# STM8AL3146 register map
Vendor: STMicroelectronics; Series: STM8L/STM8AL, medium density; File version: 1.0
CPU: other r1p0, big endian, no MPU, no FPU, 4 interrupt priority bits
Registers are 8-bit, read-write, reset 0x0 unless marked. A register's access mark holds for its fields unless they carry their own. Offsets are from the block's base; [hi:lo] are bit positions; {n}, {i} and the like mark numbered series.

## SWIM
Base 0x00007F80
0x00 CSR — SWIM control status register

## TIM1
Base 0x000052B0
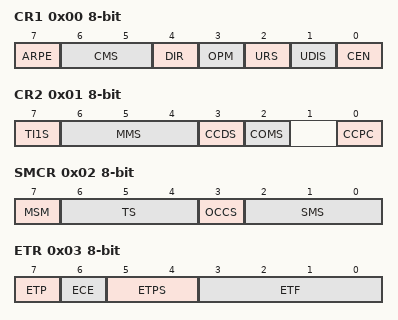
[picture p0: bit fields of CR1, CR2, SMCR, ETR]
0x00 CR1 — TIM1 control register 1
  [7] ARPE, [6:5] CMS, [4] DIR, [3] OPM, [2] URS, [1] UDIS, [0] CEN
0x01 CR2 — TIM1 control register 2
  [7] TI1S, [6:4] MMS, [3] CCDS, [2] COMS, [0] CCPC
0x02 SMCR — TIM1 Slave mode control register
  [7] MSM, [6:4] TS, [3] OCCS, [2:0] SMS
0x03 ETR — TIM1 external trigger register
  [7] ETP, [6] ECE, [5:4] ETPS, [3:0] ETF
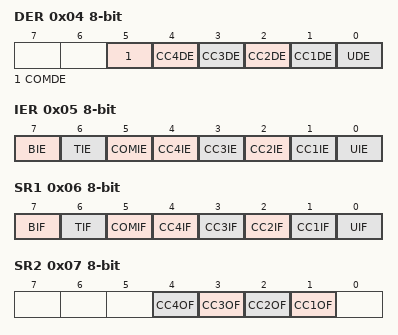
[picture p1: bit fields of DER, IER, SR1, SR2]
0x04 DER — TIM1 DMA1 request enable register
  [5] COMDE, [n] CC{n}DE (n=1..4), [0] UDE
0x05 IER — TIM1 Interrupt enable register
  [7] BIE, [6] TIE, [5] COMIE, [n] CC{n}IE (n=1..4), [0] UIE
0x06 SR1 — TIM1 status register 1
  [7] BIF, [6] TIF, [5] COMIF, [n] CC{n}IF (n=1..4), [0] UIF
0x07 SR2 — TIM1 status register 2
  [n] CC{n}OF (n=1..4)
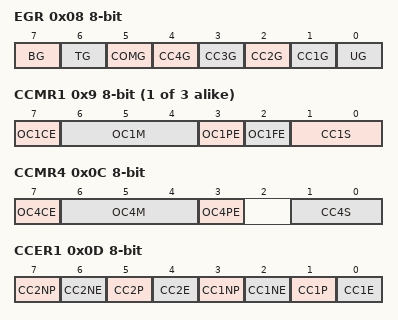
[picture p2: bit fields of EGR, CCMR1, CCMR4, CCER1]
0x08 EGR — TIM1 event generation register
  [7] BG, [6] TG, [5] COMG, [n] CC{n}G (n=1..4), [0] UG
{0x8+i} CCMR{i} (i=1..3) — TIM1 Capture/Compare mode register {i}
  [7] OC{i}CE, [6:4] OC{i}M, [3] OC{i}PE, [2] OC{i}FE, [1:0] CC{i}S
0x0C CCMR4 — TIM1 Capture/Compare mode register 4
  [7] OC4CE, [6:4] OC4M, [3] OC4PE, [1:0] CC4S
0x0D CCER1 — TIM1 Capture/Compare enable register 1
  [7] CC2NP, [6] CC2NE, [5] CC2P, [4] CC2E, [3] CC1NP, [2] CC1NE, [1] CC1P, [0] CC1E
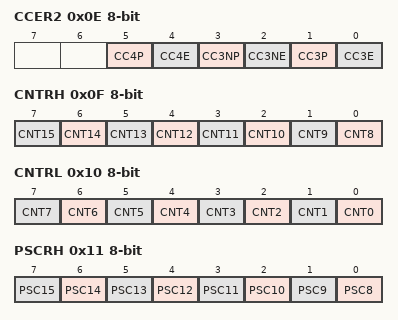
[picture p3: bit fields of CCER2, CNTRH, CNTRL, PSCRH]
0x0E CCER2 — TIM1 Capture/Compare enable register 2
  [5] CC4P, [4] CC4E, [3] CC3NP, [2] CC3NE, [1] CC3P, [0] CC3E
0x0F CNTRH — TIM1 counter high
  [n-8] CNT{n} (n=8..15)
0x10 CNTRL — TIM1 counter low
  [n] CNT{n} (n=0..7)
0x11 PSCRH — TIM1 prescaler register high
  [n-8] PSC{n} (n=8..15)
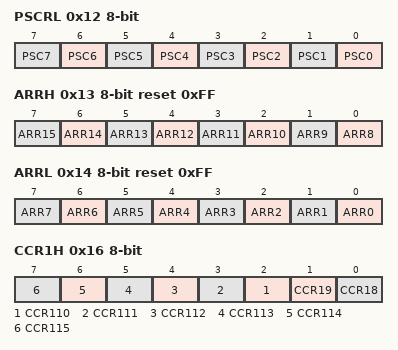
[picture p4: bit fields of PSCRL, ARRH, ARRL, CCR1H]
0x12 PSCRL — TIM1 prescaler register low
  [n] PSC{n} (n=0..7)
0x13 ARRH reset 0xFF — TIM1 Auto-reload register high
  [n-8] ARR{n} (n=8..15)
0x14 ARRL reset 0xFF — TIM1 Auto-reload register low
  [n] ARR{n} (n=0..7)
0x15 RCR — TIM1 Repetition counter register
  [7:0] REP
0x16 CCR1H — TIM1 Capture/Compare register 1 high
  [n-108] CCR{n} (n=110..115), [1] CCR19, [0] CCR18
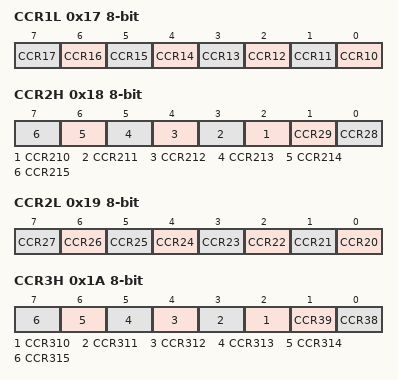
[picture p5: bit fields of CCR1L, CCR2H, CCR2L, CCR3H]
0x17 CCR1L — TIM1 Capture/Compare register 1 low
  [n-10] CCR{n} (n=10..17)
0x18 CCR2H — TIM1 Capture/Compare register 2 high
  [n-208] CCR{n} (n=210..215), [1] CCR29, [0] CCR28
0x19 CCR2L — TIM1 Capture/Compare register 2 low
  [n-20] CCR{n} (n=20..27)
0x1A CCR3H — TIM1 Capture/Compare register 3 high
  [n-308] CCR{n} (n=310..315), [1] CCR39, [0] CCR38
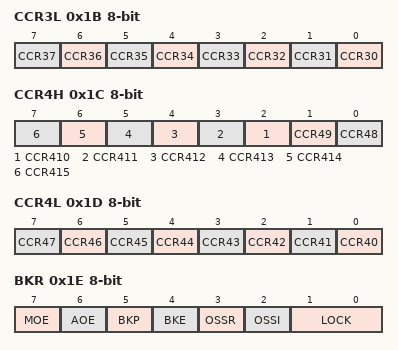
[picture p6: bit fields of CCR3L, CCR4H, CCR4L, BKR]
0x1B CCR3L — TIM1 Capture/Compare register 3 low
  [n-30] CCR{n} (n=30..37)
0x1C CCR4H — TIM1 Capture/Compare register 4 high
  [n-408] CCR{n} (n=410..415), [1] CCR49, [0] CCR48
0x1D CCR4L — TIM1 Capture/Compare register 4 low
  [n-40] CCR{n} (n=40..47)
0x1E BKR — TIM1 break register
  [7] MOE, [6] AOE, [5] BKP, [4] BKE, [3] OSSR, [2] OSSI, [1:0] LOCK
0x1F DTR — TIM1 dead-time register
  [7:0] DTG
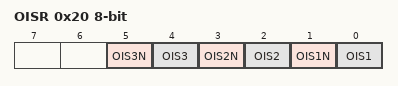
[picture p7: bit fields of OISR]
0x20 OISR — TIM1 output idle state register
  [5] OIS3N, [4] OIS3, [3] OIS2N, [2] OIS2, [1] OIS1N, [0] OIS1
0x21 DCR1 — DMA1 control register 1
  [4:0] DBA
0x22 DCR2 — TIM1 DMA1 control register 2
  [4:0] DBL
0x23 DMA1R — TIM1 DMA1 address for burst mode
  [7:0] DMAB

## TIM2
Base 0x00005250
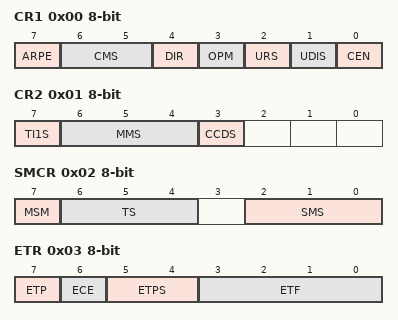
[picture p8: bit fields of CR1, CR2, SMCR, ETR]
0x00 CR1 — TIM2 control register 1
  [7] ARPE, [6:5] CMS, [4] DIR, [3] OPM, [2] URS, [1] UDIS, [0] CEN
0x01 CR2 — TIM2 control register 2
  [7] TI1S, [6:4] MMS, [3] CCDS
0x02 SMCR — TIM2 Slave mode control register
  [7] MSM, [6:4] TS, [2:0] SMS
0x03 ETR — TIM2 external trigger register
  [7] ETP, [6] ECE, [5:4] ETPS, [3:0] ETF
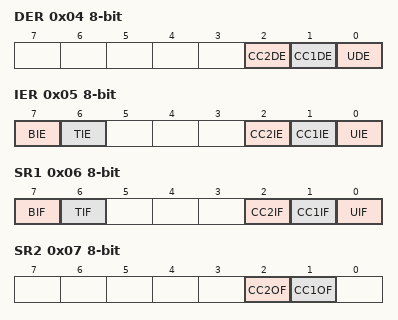
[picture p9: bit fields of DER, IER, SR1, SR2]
0x04 DER — TIM2 DMA1 request enable register
  [2] CC2DE, [1] CC1DE, [0] UDE
0x05 IER — TIM2 interrupt enable register
  [7] BIE, [6] TIE, [2] CC2IE, [1] CC1IE, [0] UIE
0x06 SR1 — TIM2 status register 1
  [7] BIF, [6] TIF, [2] CC2IF, [1] CC1IF, [0] UIF
0x07 SR2 — TIM2 status register 2
  [2] CC2OF, [1] CC1OF
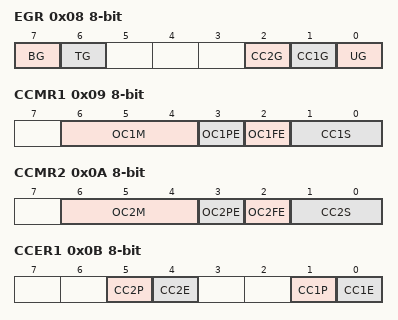
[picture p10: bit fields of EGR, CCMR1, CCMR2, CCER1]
0x08 EGR — TIM2 event generation register
  [7] BG, [6] TG, [2] CC2G, [1] CC1G, [0] UG
0x09 CCMR1 — TIM2 capture/compare mode register 1
  [6:4] OC1M, [3] OC1PE, [2] OC1FE, [1:0] CC1S
0x0A CCMR2 — TIM2 capture/compare mode register 2
  [6:4] OC2M, [3] OC2PE, [2] OC2FE, [1:0] CC2S
0x0B CCER1 — TIM2 capture/compare enable register 1
  [5] CC2P, [4] CC2E, [1] CC1P, [0] CC1E
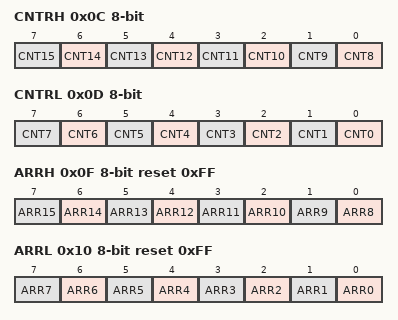
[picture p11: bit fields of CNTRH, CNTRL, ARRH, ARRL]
0x0C CNTRH — TIM2 counter high
  [n-8] CNT{n} (n=8..15)
0x0D CNTRL — TIM2 counter low
  [n] CNT{n} (n=0..7)
0x0E PSCR — TIM2 prescaler register
  [2:0] PSC
0x0F ARRH reset 0xFF — TIM2 auto-reload register high
  [n-8] ARR{n} (n=8..15)
0x10 ARRL reset 0xFF — TIM2 auto-reload register low
  [n] ARR{n} (n=0..7)
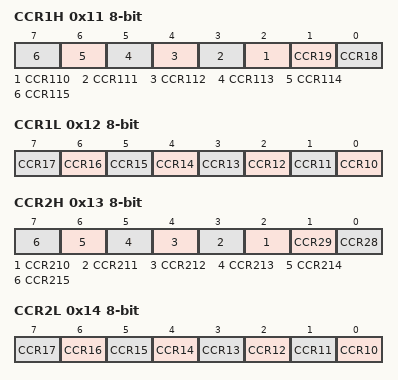
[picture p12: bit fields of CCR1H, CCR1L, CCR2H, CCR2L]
0x11 CCR1H — TIM2 capture/compare register 1 high
  [n-108] CCR{n} (n=110..115), [1] CCR19, [0] CCR18
0x12 CCR1L — TIM2 capture/compare register 1 low
  [n-10] CCR{n} (n=10..17)
0x13 CCR2H — TIM2 capture/compare register 2 high
  [n-208] CCR{n} (n=210..215), [1] CCR29, [0] CCR28
0x14 CCR2L — TIM2 capture/compare register 2 low
  [n-10] CCR{n} (n=10..17)
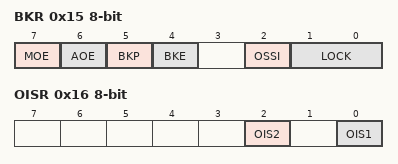
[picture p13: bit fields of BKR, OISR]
0x15 BKR — TIM2 break register
  [7] MOE, [6] AOE, [5] BKP, [4] BKE, [2] OSSI, [1:0] LOCK
0x16 OISR — TIM2 output idle state register
  [2] OIS2, [0] OIS1

## TIM3
Base 0x00005280
Registers as TIM2 (with TIM2 read as TIM3); these are added or differ:
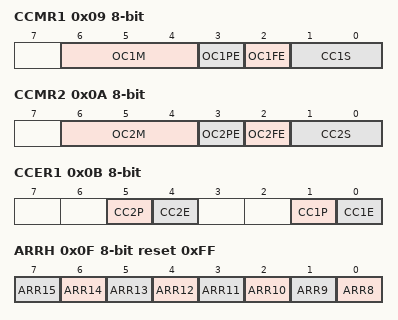
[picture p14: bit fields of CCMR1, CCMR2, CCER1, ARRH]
0x09 CCMR1 — TIM3 Capture/Compare mode register 1
  [6:4] OC1M, [3] OC1PE, [2] OC1FE, [1:0] CC1S
0x0A CCMR2 — TIM3 Capture/Compare mode register 2
  [6:4] OC2M, [3] OC2PE, [2] OC2FE, [1:0] CC2S
0x0B CCER1 — TIM3 Capture/Compare enable register 1
  [5] CC2P, [4] CC2E, [1] CC1P, [0] CC1E
0x0F ARRH reset 0xFF — TIM3 Auto-reload register high
  [n-8] ARR{n} (n=8..15)
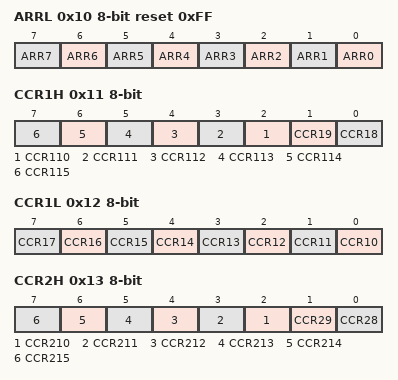
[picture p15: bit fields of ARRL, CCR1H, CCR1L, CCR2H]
0x10 ARRL reset 0xFF — TIM3 Auto-reload register low
  [n] ARR{n} (n=0..7)
0x11 CCR1H — TIM3 Capture/Compare register 1 high
  [n-108] CCR{n} (n=110..115), [1] CCR19, [0] CCR18
0x12 CCR1L — TIM3 Capture/Compare register 1 low
  [n-10] CCR{n} (n=10..17)
0x13 CCR2H — TIM3 Capture/Compare register 2 high
  [n-208] CCR{n} (n=210..215), [1] CCR29, [0] CCR28
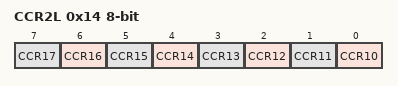
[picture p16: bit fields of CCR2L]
0x14 CCR2L — TIM3 Capture/Compare register 2 low
  [n-10] CCR{n} (n=10..17)

## TIM4
Base 0x000052E0
0x00 CR1 — TIM4 control register 1
  [7] ARPE, [3] OPM, [2] URS, [1] UDIS, [0] CEN
0x01 CR2 — TIM4 control register 2
  [6:4] MMS
0x02 SMCR — TIM4 Slave mode control register
  [7] MSM, [6:4] TS, [2:0] SMS
0x03 DER — TIM4 DMA1 request enable register
  [0] UDE
0x04 IER — TIM4 Interrupt enable register
  [6] TIE, [0] UIE
0x05 SR1 — TIM4 status register 1
  [6] TIF, [0] UIF
0x06 EGR — TIM4 Event generation register
  [6] TG, [0] UG
0x07 CNTR — TIM4 counter
  [n] CNT{n} (n=0..7)
0x08 PSCR — TIM4 prescaler register
  [3:0] PSC
0x09 ARR — TIM4 Auto-reload register
  [n] ARR{n} (n=0..7)

## USART1
Base 0x00005230
0x00 SR reset 0xC0 — USART1 status register
  [7] TXE, [6] TC, [5] RXNE, [4] IDLE, [3] OR, [2] NF, [1] FE, [0] PE
0x01 DR — USART1 data register
0x02 BRR1 — USART1 baud rate register 1
  [n-4] USART_DIV{n} (n=4..11)
0x03 BRR2 — USART1 baud rate register 2
  [n-8] USART_DIV{n} (n=12..15), [n] USART_DIV{n} (n=0..3)
0x04 CR1 — USART1 control register 1
  [7] R8, [6] T8, [5] USARTD, [4] M, [3] WAKE, [2] PCEN, [1] PS, [0] PIEN
0x05 CR2 — USART1 control register 2
  [7] TIEN, [6] TCIEN, [5] RIEN, [4] ILIEN, [3] TEN, [2] REN, [1] RWU, [0] SBK
0x06 CR3 — USART1 control register 3
  [5] STOP1, [4] STOP0, [3] CLKEN, [2] CPOL, [1] CPHA, [0] LBCL
0x07 CR4 — USART1 control register 4
  [n] ADD{n} (n=0..3)
0x08 CR5 — USART1 control register 5
  [7] DMAT, [6] DMAR, [5] SCEN, [4] NACK, [3] HDSEL, [2] IRLP, [1] IREN, [0] EIE
0x09 GTR — USART1 guard time register
  [7:0] GT
0x0A PSCR — USART1 prescaler register
  [7:0] PSC

## WFE
Base 0x000050A6
0x00 CR1 — WFE control register 1
  [n+4] EXTI_EV{n} (n=0..3), [3] TIM1_EV1, [2] TIM1_EV0, [1] TIM2_EV1, [0] TIM2_EV0
0x01 CR2 — WFE control register 2
  [7] ADC1_COMP_EV, [6] EXTI_EVF, [5] EXTI_EVD, [4] EXTI_EVB, [n-4] EXTI_EV{n} (n=4..7)
0x02 CR3 — WFE control register 3
  [7] DMA1CH23_EV, [6] DMA1CH01_EV, [5] USART1_EV, [4] I2C1_EV, [3] SPI1_EV, [2] TIM4_EV, [1] TIM3_EV1, [0] TIM3_EV0

## WWDG
Base 0x000050D3
0x00 CR reset 0x7F — WWDG control register
  [n] T{n} (n=0..7)
0x01 WR reset 0x7F — WWDR window register
  [n] W{n} (n=0..7)
